# EnhancedDemo register map
File version: 1
Controlled register analysis demonstration
Registers are 32-bit, read-only, no defined reset value unless marked. A register's access mark holds for its fields unless they carry their own. Offsets are from the block's base; lines under a group give offsets from that group; [hi:lo] are bit positions; {n}, {i} and the like mark numbered series; 'fields as' and 'values as' point back to an identical list; <NAME> marks a mode.

## Memory map
0x40000000 GPIOA — Base peripheral
0x40001000 GPIOB — Inherited peripheral at another base address

## GPIOA — Base peripheral
Base 0x40000000
Same registers: GPIOB 0x40001000
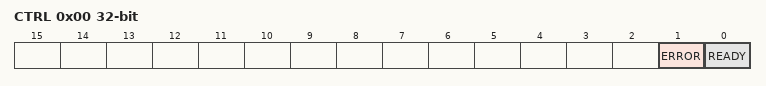
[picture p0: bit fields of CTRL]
0x00 CTRL rw — Two write-one-to-clear status flags
  [1] ERROR write-1-clears — Error status
  [0] READY write-1-clears — Ready status
{0x10+4i} DATA{i} (i=0..1) — Read-only register array
0x100 CH group — Nested channel registers
  0x04 STATUS — Channel status
